# bao1x register map
Vendor: baochip; File version: 1.0
Registers are 32-bit, read-write, reset 0x0 unless marked. A register's access mark holds for its fields unless they carry their own. Offsets are from the block's base; [hi:lo] are bit positions; {n}, {i} and the like mark numbered series; <NAME> marks a mode.

## SDDC
Base 0x50121000
0x00 SFR_IO — See `sddc.sv#L113 <https://github.com/baochip/baochip-1x/blob/main/rtl/modules/i fsub/rtl/sddc.sv#L113>`__ (line numbers are approximate)
  [1:0] sfr_io — sfr_io read/write control register
0x04 SFR_AR — See `sddc.sv#L114 <https://github.com/baochip/baochip-1x/blob/main/rtl/modules/i fsub/rtl/sddc.sv#L114>`__ (line numbers are approximate)
  [31:0] sfr_ar — sfr_ar performs action on write of value: 0x5a
0x10 CR_OCR — See `sddc.sv#L116 <https://github.com/baochip/baochip-1x/blob/main/rtl/modules/i fsub/rtl/sddc.sv#L116>`__ (line numbers are approximate)
  [23:0] cr_ocr — cr_ocr read/write control register
0x14 CR_RDFFTHRES — See `sddc.sv#L117 <https://github.com/baochip/baochip-1x/blob/main/rtl/modules/i fsub/rtl/sddc.sv#L117>`__ (line numbers are approximate)
  [7:0] cr_rdffthres — cr_rdffthres read/write control register
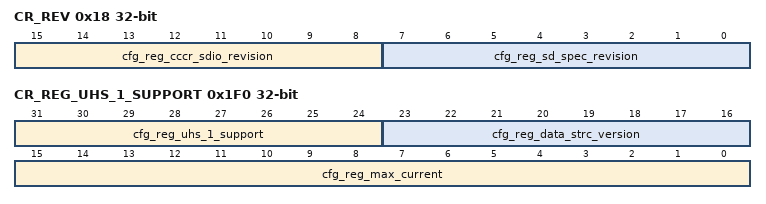
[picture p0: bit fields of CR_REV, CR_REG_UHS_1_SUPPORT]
0x18 CR_REV — See `sddc.sv#L118 <https://github.com/baochip/baochip-1x/blob/main/rtl/modules/i fsub/rtl/sddc.sv#L118>`__ (line numbers are approximate)
  [15:8] cfg_reg_cccr_sdio_revision — cfg_reg_cccr_sdio_revision read/write control register
  [7:0] cfg_reg_sd_spec_revision — cfg_reg_sd_spec_revision read/write control register
0x1C CR_BACSA — See `sddc.sv#L120 <https://github.com/baochip/baochip-1x/blob/main/rtl/modules/i fsub/rtl/sddc.sv#L120>`__ (line numbers are approximate)
  [17:0] cfg_base_addr_csa — cfg_base_addr_csa read/write control register
{0x20+4i} CR_BAIOFN_CFG_BASE_ADDR_IO_FUNC{i} (i=0..7) — See `sddc.sv#L121 <https://github.com/baochip/baochip-1x/blob/main/rtl/modules/i fsub/rtl/sddc.sv#L121>`__ (line numbers are approximate)
  [17:0] cfg_base_addr_io_func{i} — cfg_base_addr_io_func read/write control register
{0x40+4i} CR_FNCISPTR_CFG_REG_FUNC_CIS_PTR{i} (i=0..7) — See `sddc.sv#L123 <https://github.com/baochip/baochip-1x/blob/main/rtl/modules/i fsub/rtl/sddc.sv#L123>`__ (line numbers are approximate)
  [16:0] cfg_reg_func_cis_ptr{i} — cfg_reg_func_cis_ptr read/write control register
{0x60+4i} CR_FNEXTSTDCODE_CFG_REG_FUNC_EXT_STD_CODE{i} (i=0..7) — See `sddc.sv#L124 <https://github.com/baochip/baochip-1x/blob/main/rtl/modules/i fsub/rtl/sddc.sv#L124>`__ (line numbers are approximate)
  [7:0] cfg_reg_func_ext_std_code{i} — cfg_reg_func_ext_std_code read/write control register
0x80 CR_WRITE_PROTECT — See `sddc.sv#L134 <https://github.com/baochip/baochip-1x/blob/main/rtl/modules/i fsub/rtl/sddc.sv#L134>`__ (line numbers are approximate)
  [0] cr_write_protect — cr_write_protect read/write control register
0x84 CR_REG_DSR — See `sddc.sv#L135 <https://github.com/baochip/baochip-1x/blob/main/rtl/modules/i fsub/rtl/sddc.sv#L135>`__ (line numbers are approximate)
  [15:0] cr_reg_dsr — cr_reg_dsr read/write control register
{0x88+4i} CR_REG_CID_CFG_REG_CID{i} (i=0..3) — See `sddc.sv#L136 <https://github.com/baochip/baochip-1x/blob/main/rtl/modules/i fsub/rtl/sddc.sv#L136>`__ (line numbers are approximate)
  [31:0] cfg_reg_cid{i} — cr_reg_cid read/write control register
{0x98+4i} CR_REG_CSD_CFG_REG_CSD{i} (i=0..3) — See `sddc.sv#L137 <https://github.com/baochip/baochip-1x/blob/main/rtl/modules/i fsub/rtl/sddc.sv#L137>`__ (line numbers are approximate)
  [31:0] cfg_reg_csd{i} — cr_reg_csd read/write control register
0xA8 CR_REG_SCR_CFG_REG_SCR0 — See `sddc.sv#L138 <https://github.com/baochip/baochip-1x/blob/main/rtl/modules/i fsub/rtl/sddc.sv#L138>`__ (line numbers are approximate)
  [31:0] cfg_reg_scr0 — cr_reg_scr read/write control register
0xAC CR_REG_SCR_CFG_REG_SCR1 — See `sddc.sv#L138 <https://github.com/baochip/baochip-1x/blob/main/rtl/modules/i fsub/rtl/sddc.sv#L138>`__ (line numbers are approximate)
  [31:0] cfg_reg_scr1 — cr_reg_scr read/write control register
{0xB0+4i} CR_REG_SD_STATUS_CFG_REG_SD_STATUS{i} (i=0..15) — See `sddc.sv#L139 <https://github.com/baochip/baochip-1x/blob/main/rtl/modules/i fsub/rtl/sddc.sv#L139>`__ (line numbers are approximate)
  [31:0] cfg_reg_sd_status{i} — cr_reg_sd_status read/write control register
{0x100+4i} CR_BASE_ADDR_MEM_FUNC_CFG_BASE_ADDR_MEM_FUNC{i} (i=0..17) — See `sddc.sv#L142 <https://github.com/baochip/baochip-1x/blob/main/rtl/modules/i fsub/rtl/sddc.sv#L142>`__ (line numbers are approximate)
  [17:0] cfg_base_addr_mem_func{i} — cfg_base_addr_mem_func read/write control register
{0x148+4i} CR_REG_FUNC_ISDIO_INTERFACE_CODE_CFG_REG_FUNC_ISDIO_INTERFACE_CODE{i} (i=0..6) — See `sddc.sv#L150 <https://github.com/baochip/baochip-1x/blob/main/rtl/modules/i fsub/rtl/sddc.sv#L150>`__ (line numbers are approximate)
  [7:0] cfg_reg_func_isdio_interface_code{i} — cfg_reg_func_isdio_interface_code read/write control register
{0x168+4i} CR_REG_FUNC_MANUFACT_CODE_CFG_REG_FUNC_MANUFACT_CODE{i} (i=0..6) — See `sddc.sv#L151 <https://github.com/baochip/baochip-1x/blob/main/rtl/modules/i fsub/rtl/sddc.sv#L151>`__ (line numbers are approximate)
  [15:0] cfg_reg_func_manufact_code{i} — cfg_reg_func_manufact_code read/write control register
{0x188+4i} CR_REG_FUNC_MANUFACT_INFO_CFG_REG_FUNC_MANUFACT_INFO{i} (i=0..6) — See `sddc.sv#L152 <https://github.com/baochip/baochip-1x/blob/main/rtl/modules/i fsub/rtl/sddc.sv#L152>`__ (line numbers are approximate)
  [15:0] cfg_reg_func_manufact_info{i} — cfg_reg_func_manufact_info read/write control register
{0x1A8+4i} CR_REG_FUNC_ISDIO_TYPE_SUP_CODE_CFG_REG_FUNC_ISDIO_TYPE_SUP_CODE{i} (i=0..6) — See `sddc.sv#L153 <https://github.com/baochip/baochip-1x/blob/main/rtl/modules/i fsub/rtl/sddc.sv#L153>`__ (line numbers are approximate)
  [7:0] cfg_reg_func_isdio_type_sup_code{i} — cfg_reg_func_isdio_type_sup_code read/write control register
{0x1C8+4i} CR_REG_FUNC_INFO_CFG_REG_FUNC_INFO{i} (i=0..6) — See `sddc.sv#L154 <https://github.com/baochip/baochip-1x/blob/main/rtl/modules/i fsub/rtl/sddc.sv#L154>`__ (line numbers are approximate)
  [15:0] cfg_reg_func_info{i} — cfg_reg_func_info read/write control register
0x1F0 CR_REG_UHS_1_SUPPORT — See `sddc.sv#L159 <https://github.com/baochip/baochip-1x/blob/main/rtl/modules/i fsub/rtl/sddc.sv#L159>`__ (line numbers are approximate)
  [31:24] cfg_reg_uhs_1_support — cfg_reg_uhs_1_support read/write control register
  [23:16] cfg_reg_data_strc_version — cfg_reg_data_strc_version read/write control register
  [15:0] cfg_reg_max_current — cfg_reg_max_current read/write control register
